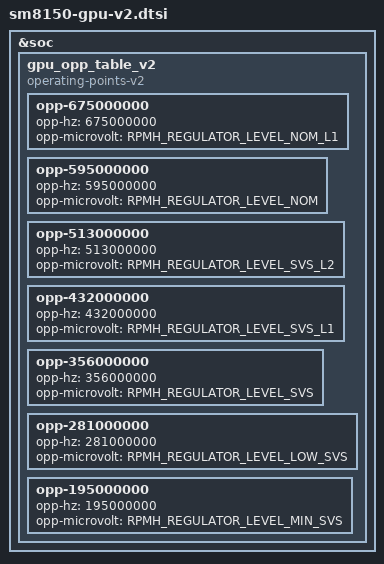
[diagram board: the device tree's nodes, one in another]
/* Copyright (c) 2018-2019, The Linux Foundation. All rights reserved.
 *
 * This program is free software; you can redistribute it and/or modify
 * it under the terms of the GNU General Public License version 2 and
 * only version 2 as published by the Free Software Foundation.
 *
 * This program is distributed in the hope that it will be useful,
 * but WITHOUT ANY WARRANTY; without even the implied warranty of
 * MERCHANTABILITY or FITNESS FOR A PARTICULAR PURPOSE.  See the
 * GNU General Public License for more details.
 */

&soc {
	gpu_opp_table_v2: gpu_opp_table_v2 {
		compatible = "operating-points-v2";

		opp-675000000 {
			opp-hz = /bits/ 64 <675000000>;
			opp-microvolt = <RPMH_REGULATOR_LEVEL_NOM_L1>;
		};

		opp-595000000 {
			opp-hz = /bits/ 64 <595000000>;
			opp-microvolt = <RPMH_REGULATOR_LEVEL_NOM>;
		};

		opp-513000000 {
			opp-hz = /bits/ 64 <513000000>;
			opp-microvolt = <RPMH_REGULATOR_LEVEL_SVS_L2>;
		};

		opp-432000000 {
			opp-hz = /bits/ 64 <432000000>;
			opp-microvolt = <RPMH_REGULATOR_LEVEL_SVS_L1>;
		};

		opp-356000000 {
			opp-hz = /bits/ 64 <356000000>;
			opp-microvolt = <RPMH_REGULATOR_LEVEL_SVS>;
		};

		opp-281000000 {
			opp-hz = /bits/ 64 <281000000>;
			opp-microvolt = <RPMH_REGULATOR_LEVEL_LOW_SVS>;
		};

		opp-195000000 {
			opp-hz = /bits/ 64 <195000000>;
			opp-microvolt = <RPMH_REGULATOR_LEVEL_MIN_SVS>;
		};
	};
};
